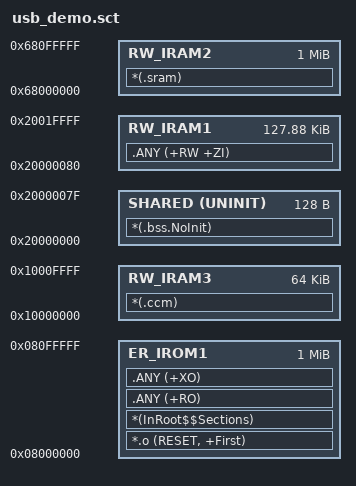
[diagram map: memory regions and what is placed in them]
; ******************************************************************
; *** Scatter-Loading Description File generated by Embedded IDE ***
; ******************************************************************

LR_IROM1 0x08000000 0x00100000 {
	ER_IROM1 0x08000000 0x00100000 {
		*.o (RESET, +First) 
		*(InRoot$$Sections) 
		.ANY (+RO) 
		.ANY (+XO) 
	}
	SHARED 0x20000000 UNINIT 0x80  {
		*(.bss.NoInit)
	}
	RW_IRAM1 0x20000000+0x80 0x00020000-0x80 {
		.ANY (+RW +ZI) 
	}
    RW_IRAM2 0x68000000 0x00100000 {
        *(.sram)
    }
    RW_IRAM3 0x10000000 0X10000 {
		*(.ccm)
    }
}

